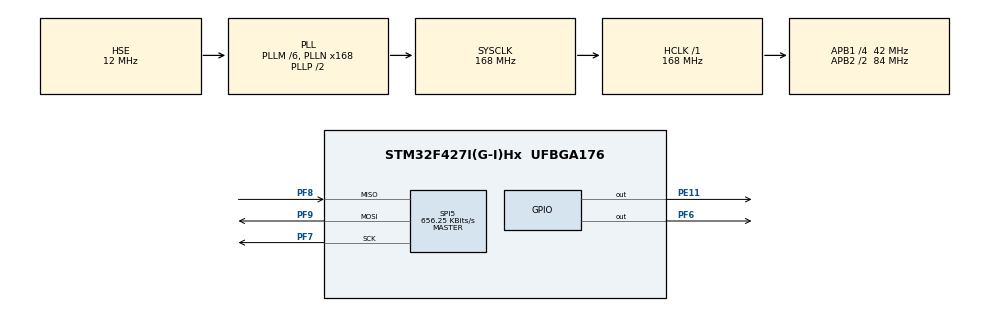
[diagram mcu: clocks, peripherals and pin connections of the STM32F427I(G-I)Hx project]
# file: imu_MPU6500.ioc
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FREERTOS.Tasks01=defaultTask,24,128,StartDefaultTask,Default,NULL,Dynamic,NULL,NULL;MPU6500,24,256,IMU_task,Default,NULL,Dynamic,NULL,NULL
Mcu.Family=STM32F4
Mcu.Name=STM32F427I(G-I)Hx
Mcu.Package=UFBGA176
NVIC.PriorityGroup=NVIC_PRIORITYGROUP_4
PA13.Mode=Serial_Wire
PA13.Signal=SYS_JTMS-SWDIO
PA14.Mode=Serial_Wire
PA14.Signal=SYS_JTCK-SWCLK
PE11.Signal=GPIO_Output
PF6.Signal=GPIO_Output
PF7.Mode=Full_Duplex_Master
PF7.Signal=SPI5_SCK
PF8.Mode=Full_Duplex_Master
PF8.Signal=SPI5_MISO
PF9.Mode=Full_Duplex_Master
PF9.Signal=SPI5_MOSI
PH0/OSC_IN.Mode=HSE-External-Oscillator
PH0/OSC_IN.Signal=RCC_OSC_IN
PH1/OSC_OUT.Mode=HSE-External-Oscillator
PH1/OSC_OUT.Signal=RCC_OSC_OUT
ProjectManager.HeapSize=0x200
ProjectManager.StackSize=0x400
ProjectManager.TargetToolchain=MDK-ARM V5
RCC.48MHZClocksFreq_Value=84000000
RCC.AHBFreq_Value=168000000
RCC.APB1CLKDivider=RCC_HCLK_DIV4
RCC.APB1Freq_Value=42000000
RCC.APB1TimFreq_Value=84000000
RCC.APB2CLKDivider=RCC_HCLK_DIV2
RCC.APB2Freq_Value=84000000
RCC.APB2TimFreq_Value=168000000
RCC.CortexFreq_Value=168000000
RCC.HCLKFreq_Value=168000000
RCC.HSE_VALUE=12000000
RCC.HSI_VALUE=16000000
RCC.LSE_VALUE=32768
RCC.PLLM=6
RCC.PLLN=168
RCC.PLLSourceVirtual=RCC_PLLSOURCE_HSE
RCC.SYSCLKFreq_VALUE=168000000
RCC.SYSCLKSource=RCC_SYSCLKSOURCE_PLLCLK
RCC.VCOOutputFreq_Value=336000000
SPI5.BaudRatePrescaler=SPI_BAUDRATEPRESCALER_128
SPI5.CalculateBaudRate=656.25 KBits/s
SPI5.Direction=SPI_DIRECTION_2LINES
SPI5.Mode=SPI_MODE_MASTER
SPI5.VirtualType=VM_MASTER
VP_FREERTOS_VS_CMSIS_V2.Mode=CMSIS_V2
board=custom

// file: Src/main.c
/* USER CODE BEGIN Header */
/**
  ******************************************************************************
  * @file           : main.c
  * @brief          : Main program body
  ******************************************************************************
  * @attention
  *
  * <h2><center>&copy; Copyright (c) 2021 STMicroelectronics.
  * All rights reserved.</center></h2>
  *
  * This software component is licensed by ST under Ultimate Liberty license
  * SLA0044, the "License"; You may not use this file except in compliance with
  * the License. You may obtain a copy of the License at:
  *                             www.st.com/SLA0044
  *
  ******************************************************************************
  */
/* USER CODE END Header */

#include "main.h"
#include "cmsis_os.h"
#include "spi.h"
#include "gpio.h"

void SystemClock_Config(void);
void MX_FREERTOS_Init(void);

int main(void)
{

  /* MCU Configuration--------------------------------------------------------*/

  /* Reset of all peripherals, Initializes the Flash interface and the Systick. */
  HAL_Init();

  /* Configure the system clock */
  SystemClock_Config();

  /* Initialize all configured peripherals */
  MX_GPIO_Init();
  MX_SPI5_Init();

  /* Call init function for freertos objects (in freertos.c) */
  MX_FREERTOS_Init();

  /* Start scheduler */
  osKernelStart();

  /* We should never get here as control is now taken by the scheduler */

  /* Infinite loop */
  while (1)
  {

  }
}

void SystemClock_Config(void)
{
  RCC_OscInitTypeDef RCC_OscInitStruct = {0};
  RCC_ClkInitTypeDef RCC_ClkInitStruct = {0};

  /** Configure the main internal regulator output voltage
  */
  __HAL_RCC_PWR_CLK_ENABLE();
  __HAL_PWR_VOLTAGESCALING_CONFIG(PWR_REGULATOR_VOLTAGE_SCALE1);
  /** Initializes the CPU, AHB and APB busses clocks
  */
  RCC_OscInitStruct.OscillatorType = RCC_OSCILLATORTYPE_HSE;
  RCC_OscInitStruct.HSEState = RCC_HSE_ON;
  RCC_OscInitStruct.PLL.PLLState = RCC_PLL_ON;
  RCC_OscInitStruct.PLL.PLLSource = RCC_PLLSOURCE_HSE;
  RCC_OscInitStruct.PLL.PLLM = 6;
  RCC_OscInitStruct.PLL.PLLN = 168;
  RCC_OscInitStruct.PLL.PLLP = RCC_PLLP_DIV2;
  RCC_OscInitStruct.PLL.PLLQ = 4;
  if (HAL_RCC_OscConfig(&RCC_OscInitStruct) != HAL_OK)
  {
    Error_Handler();
  }
  /** Initializes the CPU, AHB and APB busses clocks
  */
  RCC_ClkInitStruct.ClockType = RCC_CLOCKTYPE_HCLK|RCC_CLOCKTYPE_SYSCLK
                              |RCC_CLOCKTYPE_PCLK1|RCC_CLOCKTYPE_PCLK2;
  RCC_ClkInitStruct.SYSCLKSource = RCC_SYSCLKSOURCE_PLLCLK;
  RCC_ClkInitStruct.AHBCLKDivider = RCC_SYSCLK_DIV1;
  RCC_ClkInitStruct.APB1CLKDivider = RCC_HCLK_DIV4;
  RCC_ClkInitStruct.APB2CLKDivider = RCC_HCLK_DIV2;

  if (HAL_RCC_ClockConfig(&RCC_ClkInitStruct, FLASH_LATENCY_5) != HAL_OK)
  {
    Error_Handler();
  }
}

void Error_Handler(void)
{
}

/************************ (C) COPYRIGHT STMicroelectronics *****END OF FILE****/

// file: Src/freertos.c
/* USER CODE BEGIN Header */
/**
  ******************************************************************************
  * File Name          : freertos.c
  * Description        : Code for freertos applications
  ******************************************************************************
  * @attention
  *
  * <h2><center>&copy; Copyright (c) 2021 STMicroelectronics.
  * All rights reserved.</center></h2>
  *
  * This software component is licensed by ST under Ultimate Liberty license
  * SLA0044, the "License"; You may not use this file except in compliance with
  * the License. You may obtain a copy of the License at:
  *                             www.st.com/SLA0044
  *
  ******************************************************************************
  */
/* USER CODE END Header */

#include "FreeRTOS.h"
#include "task.h"
#include "main.h"
#include "cmsis_os.h"

/* USER CODE BEGIN Includes */
#include "MPU6500.h"
/* USER CODE END Includes */

osThreadId_t defaultTaskHandle;
osThreadId_t MPU6500Handle;

void StartDefaultTask(void *argument);
void IMU_task(void *argument);

void MX_FREERTOS_Init(void); /* (MISRA C 2004 rule 8.1) */

void MX_FREERTOS_Init(void) {
osKernelInitialize();

  /* Create the thread(s) */
  /* definition and creation of defaultTask */
  const osThreadAttr_t defaultTask_attributes = {
    .name = "defaultTask",
    .priority = (osPriority_t) osPriorityNormal,
    .stack_size = 128
  };
  defaultTaskHandle = osThreadNew(StartDefaultTask, NULL, &defaultTask_attributes);

  /* definition and creation of MPU6500 */
  const osThreadAttr_t MPU6500_attributes = {
    .name = "MPU6500",
    .priority = (osPriority_t) osPriorityNormal,
    .stack_size = 256
  };
  MPU6500Handle = osThreadNew(IMU_task, NULL, &MPU6500_attributes);

}

void StartDefaultTask(void *argument)
{
  for(;;)
  {
    osDelay(1);
  }
}

void IMU_task(void *argument)
{
  /* USER CODE BEGIN IMU_task */
	mpu_device_init();
	HAL_GPIO_WritePin(GPIOF, GPIO_PIN_6, GPIO_PIN_SET);
  /* Infinite loop */
  for(;;)
  {
		mpu_get_data();
		imu_ahrs_update();
		imu_attitude_update();
		osDelay(50);

		HAL_GPIO_TogglePin(GPIOE,GPIO_PIN_11);
    osDelay(1);
  }
  /* USER CODE END IMU_task */
}

/************************ (C) COPYRIGHT STMicroelectronics *****END OF FILE****/
